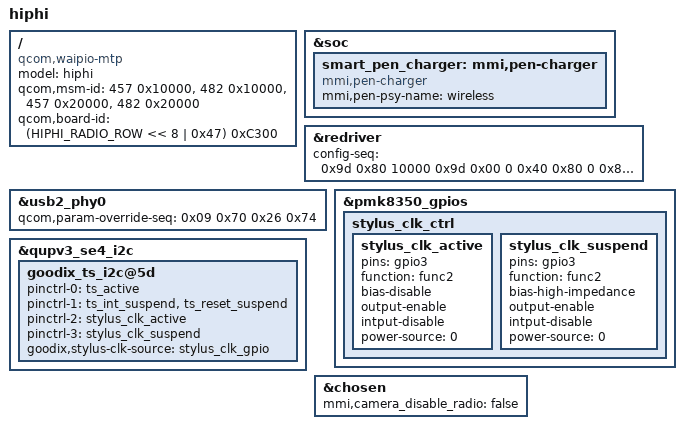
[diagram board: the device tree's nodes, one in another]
/* Copyright (c) 2021, The Linux Foundation. All rights reserved.
 *
 * This program is free software; you can redistribute it and/or modify
 * it under the terms of the GNU General Public License version 2 and
 * only version 2 as published by the Free Software Foundation.
 *
 * This program is distributed in the hope that it will be useful,
 * but WITHOUT ANY WARRANTY; without even the implied warranty of
 * MERCHANTABILITY or FITNESS FOR A PARTICULAR PURPOSE.  See the
 * GNU General Public License for more details.
 */

/dts-v1/;
/plugin/;

#include "waipio-hiphi-row-common-overlay.dtsi"
#include "waipio-hiphi-evt-sensor-overlay.dtsi"
#include "waipio-hiphi-charger-overlay.dtsi"

#define HIPHI_RADIO_ROW 3

/ {
	model = "hiphi";
	compatible = "qcom,waipio-mtp", "qcom,waipio", "qcom,mtp", "moto,hiphi";
	qcom,msm-id = <457 0x10000>, <482 0x10000>, <457 0x20000>, <482 0x20000>;
	qcom,board-id = <(HIPHI_RADIO_ROW << 8 | 0x47) 0xC300>;
};

&soc {
	smart_pen_charger: mmi,pen-charger {
		compatible = "mmi,pen-charger";
		mmi,pen-psy-name = "wireless";
	};
};

&redriver {
    config-seq =
    /* <reg_offset, value, delay_us> */
    <0x9d 0x80 10000
    0x9d 0x00 0
    0x40 0x80 0
    0x8d 0x01 0
    0x90 0x01 0
    0x51 0x87 0
    0x50 0x20 0
    0x54 0x11 0
    0x5d 0x66 0
    0x52 0x50 0
    0x55 0x00 0
    0x56 0x00 0
    0x57 0x00 0
    0x58 0x00 0
    0x59 0x00 0
    0x5a 0x00 0
    0x5b 0x00 0
    0x5e 0x07 0
    0x5f 0x00 0
    0x60 0x00 0
    0x61 0x03 0
    0x65 0x40 0
    0x66 0x00 0
    0x67 0x03 0
    0x75 0x0c 0
    0x77 0x00 0
    0x78 0x7c 0>;
};

&usb2_phy0 {
    qcom,param-override-seq =
        <0x09 0x70
        0x26 0x74>;
};

&pmk8350_gpios {
    stylus_clk_ctrl {
        stylus_clk_active: stylus_clk_active {
            pins = "gpio3";
            function = "func2";
            bias-disable; /* No Pull*/
            output-enable; /* digital output, no invert */
            intput-disable; /* prevent GPIO from being set to DIO */
            power-source = <0>;
        };
        stylus_clk_suspend: stylus_clk_suspend {
            pins = "gpio3";
            function = "func2";
            bias-high-impedance;
            output-enable; /* digital output, no invert */
            intput-disable; /* prevent GPIO from being set to DIO */
            power-source = <0>;
        };
    };
};

&qupv3_se4_i2c {
    goodix_ts_i2c@5d {
        pinctrl-names = "pmx_ts_active", "pmx_ts_suspend", "stylus_clk_active", "stylus_clk_suspend";
        pinctrl-0 = <&ts_active>;
        pinctrl-1 = <&ts_int_suspend &ts_reset_suspend>;
        pinctrl-2 = <&stylus_clk_active>;
        pinctrl-3 = <&stylus_clk_suspend>;
        goodix,stylus-clk-source = "stylus_clk_gpio"; /* use gpio3 as stylus clk*/
    };
};

&chosen {
  mmi,camera_disable_radio = "false";
};
